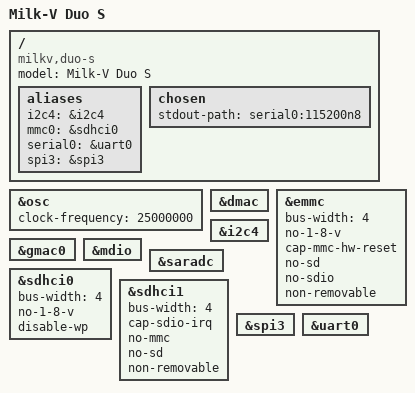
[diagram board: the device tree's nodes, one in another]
// SPDX-License-Identifier: (GPL-2.0 OR MIT)

/dts-v1/;

#include "sg2000.dtsi"

/ {
	model = "Milk-V Duo S";
	compatible = "milkv,duo-s", "sophgo,sg2000";

	aliases {
		i2c4 = &i2c4;
		mmc0 = &sdhci0;
		serial0 = &uart0;
		spi3 = &spi3;
	};

	chosen {
		stdout-path = "serial0:115200n8";
	};
};

&osc {
	clock-frequency = <25000000>;
};

&dmac {
	status = "okay";
};

&emmc {
	bus-width = <4>;
	no-1-8-v;
	cap-mmc-hw-reset;
	no-sd;
	no-sdio;
	non-removable;
	status = "okay";
};

&gmac0 {
	status = "okay";
};

&i2c4 {
	status = "okay";
};

&mdio {
	status = "okay";
};

&saradc {
	status = "okay";
};

&sdhci0 {
	bus-width = <4>;
	no-1-8-v;
	disable-wp;
	status = "okay";
};

&sdhci1 {
	bus-width = <4>;
	cap-sdio-irq;
	no-mmc;
	no-sd;
	non-removable;
	status = "okay";
};

&spi3 {
	status = "okay";
};

&uart0 {
	status = "okay";
};

